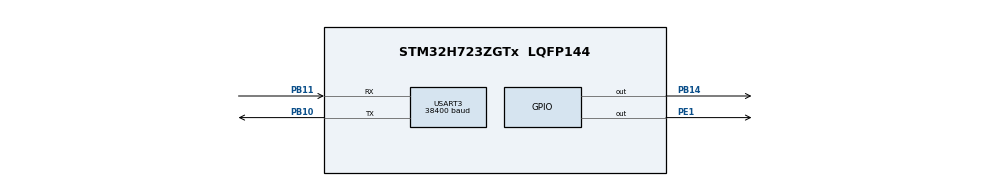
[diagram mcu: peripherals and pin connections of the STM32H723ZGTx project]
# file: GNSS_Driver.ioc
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CORTEX_M7.default_mode_Activation=1
Dma.Request0=USART3_RX
Dma.Request1=USART3_TX
Dma.USART3_RX.0.Direction=DMA_PERIPH_TO_MEMORY
Dma.USART3_RX.0.EventEnable=DISABLE
Dma.USART3_RX.0.FIFOMode=DMA_FIFOMODE_DISABLE
Dma.USART3_RX.0.Instance=DMA1_Stream0
Dma.USART3_RX.0.MemDataAlignment=DMA_MDATAALIGN_BYTE
Dma.USART3_RX.0.MemInc=DMA_MINC_ENABLE
Dma.USART3_RX.0.Mode=DMA_CIRCULAR
Dma.USART3_RX.0.PeriphDataAlignment=DMA_PDATAALIGN_BYTE
Dma.USART3_RX.0.PeriphInc=DMA_PINC_DISABLE
Dma.USART3_RX.0.Polarity=HAL_DMAMUX_REQ_GEN_RISING
Dma.USART3_RX.0.Priority=DMA_PRIORITY_LOW
Dma.USART3_RX.0.RequestNumber=1
Dma.USART3_RX.0.SignalID=NONE
Dma.USART3_RX.0.SyncEnable=DISABLE
Dma.USART3_RX.0.SyncPolarity=HAL_DMAMUX_SYNC_NO_EVENT
Dma.USART3_RX.0.SyncRequestNumber=1
Dma.USART3_RX.0.SyncSignalID=NONE
Dma.USART3_TX.1.Direction=DMA_MEMORY_TO_PERIPH
Dma.USART3_TX.1.EventEnable=DISABLE
Dma.USART3_TX.1.FIFOMode=DMA_FIFOMODE_DISABLE
Dma.USART3_TX.1.Instance=DMA1_Stream1
Dma.USART3_TX.1.MemDataAlignment=DMA_MDATAALIGN_BYTE
Dma.USART3_TX.1.MemInc=DMA_MINC_ENABLE
Dma.USART3_TX.1.Mode=DMA_NORMAL
Dma.USART3_TX.1.PeriphDataAlignment=DMA_PDATAALIGN_BYTE
Dma.USART3_TX.1.PeriphInc=DMA_PINC_DISABLE
Dma.USART3_TX.1.Polarity=HAL_DMAMUX_REQ_GEN_RISING
Dma.USART3_TX.1.Priority=DMA_PRIORITY_LOW
Dma.USART3_TX.1.RequestNumber=1
Dma.USART3_TX.1.SignalID=NONE
Dma.USART3_TX.1.SyncEnable=DISABLE
Dma.USART3_TX.1.SyncPolarity=HAL_DMAMUX_SYNC_NO_EVENT
Dma.USART3_TX.1.SyncRequestNumber=1
Dma.USART3_TX.1.SyncSignalID=NONE
Mcu.Family=STM32H7
Mcu.Name=STM32H723ZGTx
Mcu.Package=LQFP144
NVIC.DMA1_Stream0_IRQn=true\:0\:0\:false\:false\:true\:false\:true\:true
NVIC.DMA1_Stream1_IRQn=true\:0\:0\:false\:false\:true\:false\:true\:true
NVIC.PriorityGroup=NVIC_PRIORITYGROUP_4
NVIC.USART3_IRQn=true\:3\:0\:true\:false\:true\:true\:true\:true
PB10.Mode=Asynchronous
PB10.Signal=USART3_TX
PB11.Mode=Asynchronous
PB11.Signal=USART3_RX
PB14.Signal=GPIO_Output
PE1.Signal=GPIO_Output
PH0-OSC_IN.Mode=HSE-External-Oscillator
PH0-OSC_IN.Signal=RCC_OSC_IN
PH1-OSC_OUT.Mode=HSE-External-Oscillator
PH1-OSC_OUT.Signal=RCC_OSC_OUT
ProjectManager.HeapSize=0x200
ProjectManager.StackSize=0x400
ProjectManager.TargetToolchain=STM32CubeIDE
RCC.ADCFreq_Value=16125000
RCC.APB1Freq_Value=137500000
RCC.APB2Freq_Value=137500000
RCC.APB3Freq_Value=137500000
RCC.APB4Freq_Value=137500000
RCC.CortexFreq_Value=275000000
RCC.D1PPRE=RCC_APB3_DIV2
RCC.D2PPRE1=RCC_APB1_DIV2
RCC.D2PPRE2=RCC_APB2_DIV2
RCC.D3PPRE=RCC_APB4_DIV2
RCC.DIVM1=1
RCC.DIVN1=34
RCC.DIVP1=1
RCC.HCLKFreq_Value=275000000
RCC.HSE_VALUE=8000000
RCC.PLLFRACN=3072
RCC.PLLSourceVirtual=RCC_PLLSOURCE_HSE
RCC.SYSCLKFreq_VALUE=275000000
RCC.SYSCLKSource=RCC_SYSCLKSOURCE_PLLCLK
RCC.USBFreq_Value=137500000
USART3.BaudRate=38400
USART3.VirtualMode-Asynchronous=VM_ASYNC
VP_MEMORYMAP_VS_MEMORYMAP.Mode=CurAppReg
board=custom

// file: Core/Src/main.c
/* USER CODE BEGIN Header */
/**
  ******************************************************************************
  * @file           : main.c
  * @brief          : Main program body
  ******************************************************************************
  * @attention
  *
  * Copyright (c) 2024 STMicroelectronics.
  * All rights reserved.
  *
  * This software is licensed under terms that can be found in the LICENSE file
  * in the root directory of this software component.
  * If no LICENSE file comes with this software, it is provided AS-IS.
  *
  ******************************************************************************
  */
/* USER CODE END Header */
#include "main.h"

/* USER CODE BEGIN Includes */
#include "GNSS.h"
/* USER CODE END Includes */

UART_HandleTypeDef huart3;
DMA_HandleTypeDef hdma_usart3_rx;
DMA_HandleTypeDef hdma_usart3_tx;

/* USER CODE BEGIN PV */
GNSS GNSS_t;
int a=0;
/* USER CODE END PV */

void SystemClock_Config(void);
static void MPU_Config(void);
static void MX_GPIO_Init(void);
static void MX_DMA_Init(void);
static void MX_USART3_UART_Init(void);

/* USER CODE BEGIN 0 */
unsigned char data=0;
uint8_t uart_buffer[501];
/* USER CODE END 0 */

int main(void)
{

  /* MPU Configuration--------------------------------------------------------*/
  MPU_Config();

  /* MCU Configuration--------------------------------------------------------*/

  /* Reset of all peripherals, Initializes the Flash interface and the Systick. */
  HAL_Init();

  /* Configure the system clock */
  SystemClock_Config();

  /* Initialize all configured peripherals */
  MX_GPIO_Init();
  MX_DMA_Init();
  MX_USART3_UART_Init();
  /* USER CODE BEGIN 2 */
  //HAL_UART_Receive_IT(&huart3, &data,1);
  //HAL_UART_Receive_DMA(&huart3, uart_buffer, 500);
  HAL_GPIO_WritePin(GPIOB,GPIO_PIN_14,1);
  HAL_GPIO_WritePin(GPIOE,GPIO_PIN_1,1);
  GNSS_Tanimla(&GNSS_t);
  //U_Blox_frame.payload
  //data_arr[0]=U_Blox_frame.payload.U_Blox_Payload_Cfg_Prt_t.baudrate;
  /* USER CODE END 2 */

  /* Infinite loop */
  while (1)
  {

    /* USER CODE BEGIN 3 */
	    GNSS_Gorev(&GNSS_t);
	    a=DMA1_Stream0->NDTR;
  }
  /* USER CODE END 3 */
}

void SystemClock_Config(void)
{
  RCC_OscInitTypeDef RCC_OscInitStruct = {0};
  RCC_ClkInitTypeDef RCC_ClkInitStruct = {0};

  /** Supply configuration update enable
  */
  HAL_PWREx_ConfigSupply(PWR_LDO_SUPPLY);

  /** Configure the main internal regulator output voltage
  */
  __HAL_PWR_VOLTAGESCALING_CONFIG(PWR_REGULATOR_VOLTAGE_SCALE0);

  while(!__HAL_PWR_GET_FLAG(PWR_FLAG_VOSRDY)) {}

  /** Initializes the RCC Oscillators according to the specified parameters
  * in the RCC_OscInitTypeDef structure.
  */
  RCC_OscInitStruct.OscillatorType = RCC_OSCILLATORTYPE_HSE;
  RCC_OscInitStruct.HSEState = RCC_HSE_ON;
  RCC_OscInitStruct.PLL.PLLState = RCC_PLL_ON;
  RCC_OscInitStruct.PLL.PLLSource = RCC_PLLSOURCE_HSE;
  RCC_OscInitStruct.PLL.PLLM = 1;
  RCC_OscInitStruct.PLL.PLLN = 34;
  RCC_OscInitStruct.PLL.PLLP = 1;
  RCC_OscInitStruct.PLL.PLLQ = 2;
  RCC_OscInitStruct.PLL.PLLR = 2;
  RCC_OscInitStruct.PLL.PLLRGE = RCC_PLL1VCIRANGE_3;
  RCC_OscInitStruct.PLL.PLLVCOSEL = RCC_PLL1VCOWIDE;
  RCC_OscInitStruct.PLL.PLLFRACN = 3072;
  if (HAL_RCC_OscConfig(&RCC_OscInitStruct) != HAL_OK)
  {
    Error_Handler();
  }

  /** Initializes the CPU, AHB and APB buses clocks
  */
  RCC_ClkInitStruct.ClockType = RCC_CLOCKTYPE_HCLK|RCC_CLOCKTYPE_SYSCLK
                              |RCC_CLOCKTYPE_PCLK1|RCC_CLOCKTYPE_PCLK2
                              |RCC_CLOCKTYPE_D3PCLK1|RCC_CLOCKTYPE_D1PCLK1;
  RCC_ClkInitStruct.SYSCLKSource = RCC_SYSCLKSOURCE_PLLCLK;
  RCC_ClkInitStruct.SYSCLKDivider = RCC_SYSCLK_DIV1;
  RCC_ClkInitStruct.AHBCLKDivider = RCC_HCLK_DIV1;
  RCC_ClkInitStruct.APB3CLKDivider = RCC_APB3_DIV2;
  RCC_ClkInitStruct.APB1CLKDivider = RCC_APB1_DIV2;
  RCC_ClkInitStruct.APB2CLKDivider = RCC_APB2_DIV2;
  RCC_ClkInitStruct.APB4CLKDivider = RCC_APB4_DIV2;

  if (HAL_RCC_ClockConfig(&RCC_ClkInitStruct, FLASH_LATENCY_3) != HAL_OK)
  {
    Error_Handler();
  }
}

static void MX_USART3_UART_Init(void)
{

  huart3.Instance = USART3;
  huart3.Init.BaudRate = 38400;
  huart3.Init.WordLength = UART_WORDLENGTH_8B;
  huart3.Init.StopBits = UART_STOPBITS_1;
  huart3.Init.Parity = UART_PARITY_NONE;
  huart3.Init.Mode = UART_MODE_TX_RX;
  huart3.Init.HwFlowCtl = UART_HWCONTROL_NONE;
  huart3.Init.OverSampling = UART_OVERSAMPLING_16;
  huart3.Init.OneBitSampling = UART_ONE_BIT_SAMPLE_DISABLE;
  huart3.Init.ClockPrescaler = UART_PRESCALER_DIV1;
  huart3.AdvancedInit.AdvFeatureInit = UART_ADVFEATURE_NO_INIT;
  if (HAL_UART_Init(&huart3) != HAL_OK)
  {
    Error_Handler();
  }
  if (HAL_UARTEx_SetTxFifoThreshold(&huart3, UART_TXFIFO_THRESHOLD_1_8) != HAL_OK)
  {
    Error_Handler();
  }
  if (HAL_UARTEx_SetRxFifoThreshold(&huart3, UART_RXFIFO_THRESHOLD_1_8) != HAL_OK)
  {
    Error_Handler();
  }
  if (HAL_UARTEx_DisableFifoMode(&huart3) != HAL_OK)
  {
    Error_Handler();
  }

}

static void MX_DMA_Init(void)
{

  /* DMA controller clock enable */
  __HAL_RCC_DMA1_CLK_ENABLE();

  /* DMA interrupt init */
  /* DMA1_Stream0_IRQn interrupt configuration */
  HAL_NVIC_SetPriority(DMA1_Stream0_IRQn, 0, 0);
  HAL_NVIC_EnableIRQ(DMA1_Stream0_IRQn);
  /* DMA1_Stream1_IRQn interrupt configuration */
  HAL_NVIC_SetPriority(DMA1_Stream1_IRQn, 0, 0);
  HAL_NVIC_EnableIRQ(DMA1_Stream1_IRQn);

}

static void MX_GPIO_Init(void)
{
  GPIO_InitTypeDef GPIO_InitStruct = {0};

  /* GPIO Ports Clock Enable */
  __HAL_RCC_GPIOH_CLK_ENABLE();
  __HAL_RCC_GPIOB_CLK_ENABLE();
  __HAL_RCC_GPIOE_CLK_ENABLE();

  /*Configure GPIO pin Output Level */
  HAL_GPIO_WritePin(GPIOB, GPIO_PIN_14, GPIO_PIN_RESET);

  /*Configure GPIO pin Output Level */
  HAL_GPIO_WritePin(GPIOE, GPIO_PIN_1, GPIO_PIN_RESET);

  /*Configure GPIO pin : PB14 */
  GPIO_InitStruct.Pin = GPIO_PIN_14;
  GPIO_InitStruct.Mode = GPIO_MODE_OUTPUT_PP;
  GPIO_InitStruct.Pull = GPIO_NOPULL;
  GPIO_InitStruct.Speed = GPIO_SPEED_FREQ_LOW;
  HAL_GPIO_Init(GPIOB, &GPIO_InitStruct);

  /*Configure GPIO pin : PE1 */
  GPIO_InitStruct.Pin = GPIO_PIN_1;
  GPIO_InitStruct.Mode = GPIO_MODE_OUTPUT_PP;
  GPIO_InitStruct.Pull = GPIO_NOPULL;
  GPIO_InitStruct.Speed = GPIO_SPEED_FREQ_LOW;
  HAL_GPIO_Init(GPIOE, &GPIO_InitStruct);

}

 /* MPU Configuration */

void MPU_Config(void)
{
  MPU_Region_InitTypeDef MPU_InitStruct = {0};

  /* Disables the MPU */
  HAL_MPU_Disable();

  /** Initializes and configures the Region and the memory to be protected
  */
  MPU_InitStruct.Enable = MPU_REGION_ENABLE;
  MPU_InitStruct.Number = MPU_REGION_NUMBER0;
  MPU_InitStruct.BaseAddress = 0x0;
  MPU_InitStruct.Size = MPU_REGION_SIZE_4GB;
  MPU_InitStruct.SubRegionDisable = 0x87;
  MPU_InitStruct.TypeExtField = MPU_TEX_LEVEL0;
  MPU_InitStruct.AccessPermission = MPU_REGION_NO_ACCESS;
  MPU_InitStruct.DisableExec = MPU_INSTRUCTION_ACCESS_DISABLE;
  MPU_InitStruct.IsShareable = MPU_ACCESS_SHAREABLE;
  MPU_InitStruct.IsCacheable = MPU_ACCESS_NOT_CACHEABLE;
  MPU_InitStruct.IsBufferable = MPU_ACCESS_NOT_BUFFERABLE;

  HAL_MPU_ConfigRegion(&MPU_InitStruct);
  /* Enables the MPU */
  HAL_MPU_Enable(MPU_PRIVILEGED_DEFAULT);

}

void Error_Handler(void)
{
  __disable_irq();
  while (1)
  {
  }
}
